AUTOSAR XML (schema 4-1-3)
standard types defined: boolean, sint8, uint16, uint32, uint8, boolean_CompuMethod, boolean_DataConstr, sint8_DataConstr, uint16_DataConstr, uint32_DataConstr, uint8_DataConstr, sint16
package /MICROSAR/Dem_swc/DataTypes
  5 x impl type:
    Dem_DebounceResetStatusType: compu {0=DEM_DEBOUNCE_STATUS_FREEZE, 1=DEM_DEBOUNCE_STATUS_RESET}, range raw 0..255, implementation-data-type=ImplementationDataTypes/uint8
    Dem_DTCFormatType: compu {0=DEM_DTC_FORMAT_OBD, 1=DEM_DTC_FORMAT_UDS, 2=DEM_DTC_FORMAT_J1939}, range raw 0..2, implementation-data-type=ImplementationDataTypes/uint8
    Dem_EventStatusType:
      compu {0=DEM_EVENT_STATUS_PASSED, 1=DEM_EVENT_STATUS_FAILED, 2=DEM_EVENT_STATUS_PREPASSED, 3=DEM_EVENT_STATUS_PREFAILED, 4=DEM_EVENT_STATUS_FDC_THRESHOLD_REACHED, 5=DEM_EVENT_STATUS_PASSED_CONDITIONS_NOT_FULFILLED, 6=DEM_EVENT_STATUS_FAILED_CONDITIONS_NOT_FULFILLED, 7=DEM_EVENT_STATUS_PREPASSED_CONDITIONS_NOT_FULFILLED, 8=DEM_EVENT_STATUS_PREFAILED_CONDITIONS_NOT_FULFILLED}
      range raw 0..255
      implementation-data-type=ImplementationDataTypes/uint8
    Dem_MaxDataValueType: category=ARRAY, sw-calibration-access=READ-ONLY
      element Dem_MaxDataValueTypeElement: array-size=14, array-size-semantics=FIXED-SIZE, implementation-data-type=ImplementationDataTypes/uint8
    Dem_UdsStatusByteType:
      compu {mask 1: 1=DEM_UDS_STATUS_TF (bit 0: TestFailed), mask 2: 2=DEM_UDS_STATUS_TFTOC (bit 1: TestFailedThisOperationCycle), mask 4: 4=DEM_UDS_STATUS_PDTC (bit 2: PendingDTC), mask 8: 8=DEM_UDS_STATUS_CDTC (bit 3: ConfirmedDTC), mask 16: 16=DEM_UDS_STATUS_TNCSLC (bit 4: TestNotCompletedSinceLastClear), mask 32: 32=DEM_UDS_STATUS_TFSLC (bit 5: TestFailedSinceLastClear), mask 64: 64=DEM_UDS_STATUS_TNCTOC (bit 6: TestNotCompletedThisOperationCycle), mask 128: 128=DEM_UDS_STATUS_WIR (bit 7: WarningIndicatorRequested)}
      range raw 0..255
      implementation-data-type=ImplementationDataTypes/uint8
package /MICROSAR/Dem_swc/Interfaces
  client server interface DiagnosticMonitor: is-service=true, service-kind=DIAGNOSTIC-EVENT-MANAGER
    11 x operation:
      GetDTCOfEvent: possible-error=[DEM_E_NO_DTC_AVAILABLE, E_NOT_OK]
        arg DTCFormat: type=Dem_DTCFormatType, direction=IN, server-argument-impl-policy=USE-ARGUMENT-TYPE
        arg DTCOfEvent: type=ImplementationDataTypes/uint32, direction=OUT, server-argument-impl-policy=USE-ARGUMENT-TYPE
      GetEventExtendedDataRecordEx: possible-error=[DEM_BUFFER_TOO_SMALL, DEM_NO_SUCH_ELEMENT, E_NOT_OK]
        arg RecordNumber: type=ImplementationDataTypes/uint8, direction=IN, server-argument-impl-policy=USE-ARGUMENT-TYPE
        arg DestBuffer: type=Dem_MaxDataValueType, direction=OUT, server-argument-impl-policy=USE-ARGUMENT-TYPE
        arg BufSize: type=ImplementationDataTypes/uint16, direction=INOUT, server-argument-impl-policy=USE-ARGUMENT-TYPE
      GetEventFailed: possible-error=E_NOT_OK
        arg EventFailed: type=ImplementationDataTypes/boolean, direction=OUT, server-argument-impl-policy=USE-ARGUMENT-TYPE
      GetEventFreezeFrameDataEx: possible-error=[DEM_BUFFER_TOO_SMALL, DEM_NO_SUCH_ELEMENT, E_NOT_OK]
        4 x arg, all with server-argument-impl-policy=USE-ARGUMENT-TYPE:
          RecordNumber: type=ImplementationDataTypes/uint8, direction=IN
          DataId: type=ImplementationDataTypes/uint16, direction=IN
          DestBuffer: type=Dem_MaxDataValueType, direction=OUT
          BufSize: type=ImplementationDataTypes/uint16, direction=INOUT
      GetEventStatus: possible-error=E_NOT_OK
        arg UDSStatusByte: type=Dem_UdsStatusByteType, direction=OUT, server-argument-impl-policy=USE-ARGUMENT-TYPE
      GetEventTested: possible-error=E_NOT_OK
        arg EventTested: type=ImplementationDataTypes/boolean, direction=OUT, server-argument-impl-policy=USE-ARGUMENT-TYPE
      GetEventUdsStatus: possible-error=E_NOT_OK
        arg UDSStatusByte: type=Dem_UdsStatusByteType, direction=OUT, server-argument-impl-policy=USE-ARGUMENT-TYPE
      GetFaultDetectionCounter: possible-error=[DEM_E_NO_FDC_AVAILABLE, E_NOT_OK]
        arg FaultDetectionCounter: type=sint8, direction=OUT, server-argument-impl-policy=USE-ARGUMENT-TYPE
      ResetEventDebounceStatus: possible-error=E_NOT_OK
        arg DebounceResetStatus: type=Dem_DebounceResetStatusType, direction=IN, server-argument-impl-policy=USE-ARGUMENT-TYPE
      ResetEventStatus: possible-error=E_NOT_OK
      SetEventStatus: possible-error=E_NOT_OK
        arg EventStatus: type=Dem_EventStatusType, direction=IN, server-argument-impl-policy=USE-ARGUMENT-TYPE
    5 x error:
      DEM_BUFFER_TOO_SMALL: error-code=21
      DEM_E_NO_DTC_AVAILABLE: error-code=10
      DEM_E_NO_FDC_AVAILABLE: error-code=14
      DEM_NO_SUCH_ELEMENT: error-code=48
      E_NOT_OK: error-code=1
package /UAES/ASW/ApplicationDataTypes
  7 x app type, all with category=VALUE, sw-calibration-access=READ-WRITE:
    I_q0p25_mA_s16: compu {phys=raw*0.25 for raw -INF..INF; unit mA}, range raw -32768..32767
    N_q1_rpm_u16: compu {phys=raw for raw -INF..INF; unit rpm}, range raw 0..65535
    P_q2_hPa_s16: compu {phys=raw*2; unit hPa}, range raw -32768..32767
    Perc_q0p0122_Perc_s16: compu {phys=raw*0.01220703125 for raw -INF..INF; unit %}, range raw -32768..32767
    T_q0p1_o273p14_DegC_s16: compu {phys=raw*0.1-273.14 for raw -INF..INF; unit DegC}, range raw -32768..32767
    Ti_q1_us_u32: compu {phys=raw for raw -INF..INF; unit us}, range phys 0..4294967295, raw 0..4294967295
    U_q1_mV_u16: compu {phys=raw for raw -INF..INF; unit mV}, range raw 0..65535
package /UAES/ASW/CompuMethods
  compu method CM_boolean: 0=FALSE, 1=TRUE
package /UAES/ASW/DataConstrs
  range DC_boolean: raw 0..1
  range DC_sint16: raw -32768..32767
  range DC_uint16: raw 0..65535
  range DC_uint32: raw 0..4294967295
  range DC_uint8: raw 0..255
package /UAES/ASW/DataTypeMappingSets
  data type mapping set DTMS_ChrgMngt_ComCnvTx
    data-type-maps:
      application-data-type=I_q0p25_mA_s16, implementation-data-type=sint16
      application-data-type=N_q1_rpm_u16, implementation-data-type=ImplementationDataTypes/uint16
      application-data-type=P_q2_hPa_s16, implementation-data-type=sint16
      application-data-type=Perc_q0p0122_Perc_s16, implementation-data-type=sint16
      application-data-type=T_q0p1_o273p14_DegC_s16, implementation-data-type=sint16
      application-data-type=Ti_q1_us_u32, implementation-data-type=ImplementationDataTypes/uint32
      application-data-type=U_q1_mV_u16, implementation-data-type=ImplementationDataTypes/uint16
package /UAES/ASW/PortInterfaces
  73 x sender receiver interface:
    AcChrgrIntkT_flgSRCMaxErr: invalidation-policy{data-element=AcChrgrIntkT_flgSRCMaxErr/Val, handle-invalid=DONT-INVALIDATE}
      data Val: sw-calibration-access=READ-ONLY, type=ImplementationDataTypes/boolean
    AcChrgrIntkT_flgSRCMinErr: invalidation-policy{data-element=AcChrgrIntkT_flgSRCMinErr/Val, handle-invalid=DONT-INVALIDATE}
      data Val: sw-calibration-access=READ-ONLY, type=ImplementationDataTypes/boolean
    AcChrgrIntkT_t: invalidation-policy{data-element=AcChrgrIntkT_t/Val, handle-invalid=DONT-INVALIDATE}
      data Val: sw-calibration-access=READ-ONLY, type=T_q0p1_o273p14_DegC_s16
    AcChrgrIntkT2_flgSRCMaxErr: invalidation-policy{data-element=AcChrgrIntkT2_flgSRCMaxErr/Val, handle-invalid=DONT-INVALIDATE}
      data Val: sw-calibration-access=READ-ONLY, type=ImplementationDataTypes/boolean
    AcChrgrIntkT2_flgSRCMinErr: invalidation-policy{data-element=AcChrgrIntkT2_flgSRCMinErr/Val, handle-invalid=DONT-INVALIDATE}
      data Val: sw-calibration-access=READ-ONLY, type=ImplementationDataTypes/boolean
    AcChrgrIntkT2_t: invalidation-policy{data-element=AcChrgrIntkT2_t/Val, handle-invalid=DONT-INVALIDATE}
      data Val: sw-calibration-access=READ-ONLY, type=T_q0p1_o273p14_DegC_s16
    BattU_bVoltEnbPinDiag: invalidation-policy{data-element=BattU_bVoltEnbPinDiag/Val, handle-invalid=DONT-INVALIDATE}
      data Val: sw-calibration-access=READ-ONLY, type=ImplementationDataTypes/boolean
    ChgrPlug_stPlgLock: invalidation-policy{data-element=ChgrPlug_stPlgLock/Val, handle-invalid=DONT-INVALIDATE}
      data Val: sw-calibration-access=READ-ONLY, type=ImplementationDataTypes/uint8
    ChrgIndcr_bBlueFaultSt: invalidation-policy{data-element=ChrgIndcr_bBlueFaultSt/Val, handle-invalid=DONT-INVALIDATE}
      data Val: sw-calibration-access=READ-ONLY, type=ImplementationDataTypes/boolean
    ChrgIndcr_bGreenFaultSt: invalidation-policy{data-element=ChrgIndcr_bGreenFaultSt/Val, handle-invalid=DONT-INVALIDATE}
      data Val: sw-calibration-access=READ-ONLY, type=ImplementationDataTypes/boolean
    ChrgIndcr_bRedFaultSt: invalidation-policy{data-element=ChrgIndcr_bRedFaultSt/Val, handle-invalid=DONT-INVALIDATE}
      data Val: sw-calibration-access=READ-ONLY, type=ImplementationDataTypes/boolean
    ChrgIndcr_rIndcr1: invalidation-policy{data-element=ChrgIndcr_rIndcr1/Val, handle-invalid=DONT-INVALIDATE}
      data Val: sw-calibration-access=READ-ONLY, type=Perc_q0p0122_Perc_s16
    ChrgIndcr_rIndcr2: invalidation-policy{data-element=ChrgIndcr_rIndcr2/Val, handle-invalid=DONT-INVALIDATE}
      data Val: sw-calibration-access=READ-ONLY, type=Perc_q0p0122_Perc_s16
    ChrgIndcr_rIndcr3: invalidation-policy{data-element=ChrgIndcr_rIndcr3/Val, handle-invalid=DONT-INVALIDATE}
      data Val: sw-calibration-access=READ-ONLY, type=Perc_q0p0122_Perc_s16
    ChrgPlgPosn_st: invalidation-policy{data-element=ChrgPlgPosn_st/Val, handle-invalid=DONT-INVALIDATE}
      data Val: sw-calibration-access=READ-ONLY, type=ImplementationDataTypes/uint8
    ChrgPlgPosn_stRaw: invalidation-policy{data-element=ChrgPlgPosn_stRaw/Val, handle-invalid=DONT-INVALIDATE}
      data Val: sw-calibration-access=READ-ONLY, type=ImplementationDataTypes/uint8
    ChrgPlgPosn_stRaw2: invalidation-policy{data-element=ChrgPlgPosn_stRaw2/Val, handle-invalid=DONT-INVALIDATE}
      data Val: sw-calibration-access=READ-ONLY, type=ImplementationDataTypes/uint8
    ComRx_u8UMM_UsageModeSt: invalidation-policy{data-element=ComRx_u8UMM_UsageModeSt/Val, handle-invalid=DONT-INVALIDATE}
      data Val: sw-calibration-access=READ-ONLY, type=ImplementationDataTypes/uint8
    ComTx_bACChgL1TempVoltOvr: invalidation-policy{data-element=ComTx_bACChgL1TempVoltOvr/Val, handle-invalid=DONT-INVALIDATE}
      data Val: sw-calibration-access=READ-ONLY, type=ImplementationDataTypes/boolean
    ComTx_bACChgL1TempVoltUnd: invalidation-policy{data-element=ComTx_bACChgL1TempVoltUnd/Val, handle-invalid=DONT-INVALIDATE}
      data Val: sw-calibration-access=READ-ONLY, type=ImplementationDataTypes/boolean
    ComTx_bACChgNTempVoltOvr: invalidation-policy{data-element=ComTx_bACChgNTempVoltOvr/Val, handle-invalid=DONT-INVALIDATE}
      data Val: sw-calibration-access=READ-ONLY, type=ImplementationDataTypes/boolean
    ComTx_bACChgNTempVoltUnd: invalidation-policy{data-element=ComTx_bACChgNTempVoltUnd/Val, handle-invalid=DONT-INVALIDATE}
      data Val: sw-calibration-access=READ-ONLY, type=ImplementationDataTypes/boolean
    ComTx_bACEleclocksSt1: invalidation-policy{data-element=ComTx_bACEleclocksSt1/Val, handle-invalid=DONT-INVALIDATE}
      data Val: sw-calibration-access=READ-ONLY, type=ImplementationDataTypes/boolean
    ComTx_bACEleclocksSt2: invalidation-policy{data-element=ComTx_bACEleclocksSt2/Val, handle-invalid=DONT-INVALIDATE}
      data Val: sw-calibration-access=READ-ONLY, type=ImplementationDataTypes/boolean
    ComTx_bDCChgDC1TempVoltOvr: invalidation-policy{data-element=ComTx_bDCChgDC1TempVoltOvr/Val, handle-invalid=DONT-INVALIDATE}
      data Val: sw-calibration-access=READ-ONLY, type=ImplementationDataTypes/boolean
    ComTx_bDCChgDC1TempVoltUnd: invalidation-policy{data-element=ComTx_bDCChgDC1TempVoltUnd/Val, handle-invalid=DONT-INVALIDATE}
      data Val: sw-calibration-access=READ-ONLY, type=ImplementationDataTypes/boolean
    ComTx_bDCChgDC2TempVoltOvr: invalidation-policy{data-element=ComTx_bDCChgDC2TempVoltOvr/Val, handle-invalid=DONT-INVALIDATE}
      data Val: sw-calibration-access=READ-ONLY, type=ImplementationDataTypes/boolean
    ComTx_bDCChgDC2TempVoltUnd: invalidation-policy{data-element=ComTx_bDCChgDC2TempVoltUnd/Val, handle-invalid=DONT-INVALIDATE}
      data Val: sw-calibration-access=READ-ONLY, type=ImplementationDataTypes/boolean
    ComTx_bDCchgpileA1voltVD: invalidation-policy{data-element=ComTx_bDCchgpileA1voltVD/Val, handle-invalid=DONT-INVALIDATE}
      data Val: sw-calibration-access=READ-ONLY, type=ImplementationDataTypes/boolean
    ComTx_bDCchgpileCC1voltVD: invalidation-policy{data-element=ComTx_bDCchgpileCC1voltVD/Val, handle-invalid=DONT-INVALIDATE}
      data Val: sw-calibration-access=READ-ONLY, type=ImplementationDataTypes/boolean
    ComTx_bDCchgpileCC2voltVD: invalidation-policy{data-element=ComTx_bDCchgpileCC2voltVD/Val, handle-invalid=DONT-INVALIDATE}
      data Val: sw-calibration-access=READ-ONLY, type=ImplementationDataTypes/boolean
    ComTx_bEL_BlueChargeLightFaultSt: invalidation-policy{data-element=ComTx_bEL_BlueChargeLightFaultSt/Val, handle-invalid=DONT-INVALIDATE}
      data Val: sw-calibration-access=READ-ONLY, type=ImplementationDataTypes/boolean
    ComTx_bEL_GreenChargeLightFaultSt: invalidation-policy{data-element=ComTx_bEL_GreenChargeLightFaultSt/Val, handle-invalid=DONT-INVALIDATE}
      data Val: sw-calibration-access=READ-ONLY, type=ImplementationDataTypes/boolean
    ComTx_bEL_RedChargeLightFaultSt: invalidation-policy{data-element=ComTx_bEL_RedChargeLightFaultSt/Val, handle-invalid=DONT-INVALIDATE}
      data Val: sw-calibration-access=READ-ONLY, type=ImplementationDataTypes/boolean
    ComTx_u16ACChgL1Temp: invalidation-policy{data-element=ComTx_u16ACChgL1Temp/Val, handle-invalid=DONT-INVALIDATE}
      data Val: sw-calibration-access=READ-ONLY, type=ImplementationDataTypes/uint16
    ComTx_u16ACChgNTemp: invalidation-policy{data-element=ComTx_u16ACChgNTemp/Val, handle-invalid=DONT-INVALIDATE}
      data Val: sw-calibration-access=READ-ONLY, type=ImplementationDataTypes/uint16
    ComTx_u16DCChgDC1Temp: invalidation-policy{data-element=ComTx_u16DCChgDC1Temp/Val, handle-invalid=DONT-INVALIDATE}
      data Val: sw-calibration-access=READ-ONLY, type=ImplementationDataTypes/uint16
    ComTx_u16DCChgDC2emp: invalidation-policy{data-element=ComTx_u16DCChgDC2emp/Val, handle-invalid=DONT-INVALIDATE}
      data Val: sw-calibration-access=READ-ONLY, type=ImplementationDataTypes/uint16
    ComTx_u16DCChgDC2Temp: invalidation-policy{data-element=ComTx_u16DCChgDC2Temp/Val, handle-invalid=DONT-INVALIDATE}
      data Val: sw-calibration-access=READ-ONLY, type=ImplementationDataTypes/uint16
    ComTx_u16DCchgpileA1volt: invalidation-policy{data-element=ComTx_u16DCchgpileA1volt/Val, handle-invalid=DONT-INVALIDATE}
      data Val: sw-calibration-access=READ-ONLY, type=ImplementationDataTypes/uint16
    ComTx_u8ACChgL1TempVD: invalidation-policy{data-element=ComTx_u8ACChgL1TempVD/Val, handle-invalid=DONT-INVALIDATE}
      data Val: sw-calibration-access=READ-ONLY, type=ImplementationDataTypes/uint8
    ComTx_u8ACChgNTempVD: invalidation-policy{data-element=ComTx_u8ACChgNTempVD/Val, handle-invalid=DONT-INVALIDATE}
      data Val: sw-calibration-access=READ-ONLY, type=ImplementationDataTypes/uint8
    ComTx_u8ACEleclocksSt: invalidation-policy{data-element=ComTx_u8ACEleclocksSt/Val, handle-invalid=DONT-INVALIDATE}
      data Val: sw-calibration-access=READ-ONLY, type=ImplementationDataTypes/uint8
    ComTx_u8DCChgDC1TempVD: invalidation-policy{data-element=ComTx_u8DCChgDC1TempVD/Val, handle-invalid=DONT-INVALIDATE}
      data Val: sw-calibration-access=READ-ONLY, type=ImplementationDataTypes/uint8
    ComTx_u8DCChgDC2TempVD: invalidation-policy{data-element=ComTx_u8DCChgDC2TempVD/Val, handle-invalid=DONT-INVALIDATE}
      data Val: sw-calibration-access=READ-ONLY, type=ImplementationDataTypes/uint8
    ComTx_u8DCchgpileCC1volt: invalidation-policy{data-element=ComTx_u8DCchgpileCC1volt/Val, handle-invalid=DONT-INVALIDATE}
      data Val: sw-calibration-access=READ-ONLY, type=ImplementationDataTypes/uint8
    ComTx_u8DCchgpileCC2volt: invalidation-policy{data-element=ComTx_u8DCchgpileCC2volt/Val, handle-invalid=DONT-INVALIDATE}
      data Val: sw-calibration-access=READ-ONLY, type=ImplementationDataTypes/uint8
    ComTx_u8EL_IndChargeLightSt: invalidation-policy{data-element=ComTx_u8EL_IndChargeLightSt/Val, handle-invalid=DONT-INVALIDATE}
      data Val: sw-calibration-access=READ-ONLY, type=ImplementationDataTypes/uint8
    ComTx_u8Elecunlockdrvst: invalidation-policy{data-element=ComTx_u8Elecunlockdrvst/Val, handle-invalid=DONT-INVALIDATE}
      data Val: sw-calibration-access=READ-ONLY, type=ImplementationDataTypes/uint8
    ComTx_u8ElecunlockM1diagnosisoupt: invalidation-policy{data-element=ComTx_u8ElecunlockM1diagnosisoupt/Val, handle-invalid=DONT-INVALIDATE}
      data Val: sw-calibration-access=READ-ONLY, type=ImplementationDataTypes/uint8
    ComTx_u8ElecunlockM1diagnosisoupt1: invalidation-policy{data-element=ComTx_u8ElecunlockM1diagnosisoupt1/Val, handle-invalid=DONT-INVALIDATE}
      data Val: sw-calibration-access=READ-ONLY, type=ImplementationDataTypes/uint8
    ComTx_u8ElecunlockM1diagnosisoupt2: invalidation-policy{data-element=ComTx_u8ElecunlockM1diagnosisoupt2/Val, handle-invalid=DONT-INVALIDATE}
      data Val: sw-calibration-access=READ-ONLY, type=ImplementationDataTypes/uint8
    ComTx_u8ElecunlockM2diagnosisoupt: invalidation-policy{data-element=ComTx_u8ElecunlockM2diagnosisoupt/Val, handle-invalid=DONT-INVALIDATE}
      data Val: sw-calibration-access=READ-ONLY, type=ImplementationDataTypes/uint8
    ComTx_u8ElecunlockM2diagnosisoupt1: invalidation-policy{data-element=ComTx_u8ElecunlockM2diagnosisoupt1/Val, handle-invalid=DONT-INVALIDATE}
      data Val: sw-calibration-access=READ-ONLY, type=ImplementationDataTypes/uint8
    ComTx_u8ElecunlockM2diagnosisoupt2: invalidation-policy{data-element=ComTx_u8ElecunlockM2diagnosisoupt2/Val, handle-invalid=DONT-INVALIDATE}
      data Val: sw-calibration-access=READ-ONLY, type=ImplementationDataTypes/uint8
    ComTx_u8ElecunlockProSt: invalidation-policy{data-element=ComTx_u8ElecunlockProSt/Val, handle-invalid=DONT-INVALIDATE}
      data Val: sw-calibration-access=READ-ONLY, type=ImplementationDataTypes/uint8
    DcChrgrIntkT_flgSRCMaxErr: invalidation-policy{data-element=DcChrgrIntkT_flgSRCMaxErr/Val, handle-invalid=DONT-INVALIDATE}
      data Val: sw-calibration-access=READ-ONLY, type=ImplementationDataTypes/boolean
    DcChrgrIntkT_flgSRCMinErr: invalidation-policy{data-element=DcChrgrIntkT_flgSRCMinErr/Val, handle-invalid=DONT-INVALIDATE}
      data Val: sw-calibration-access=READ-ONLY, type=ImplementationDataTypes/boolean
    DcChrgrIntkT_t: invalidation-policy{data-element=DcChrgrIntkT_t/Val, handle-invalid=DONT-INVALIDATE}
      data Val: sw-calibration-access=READ-ONLY, type=T_q0p1_o273p14_DegC_s16
    DcChrgrIntkT2_flgSRCMaxErr: invalidation-policy{data-element=DcChrgrIntkT2_flgSRCMaxErr/Val, handle-invalid=DONT-INVALIDATE}
      data Val: sw-calibration-access=READ-ONLY, type=ImplementationDataTypes/boolean
    DcChrgrIntkT2_flgSRCMinErr: invalidation-policy{data-element=DcChrgrIntkT2_flgSRCMinErr/Val, handle-invalid=DONT-INVALIDATE}
      data Val: sw-calibration-access=READ-ONLY, type=ImplementationDataTypes/boolean
    DcChrgrIntkT2_t: invalidation-policy{data-element=DcChrgrIntkT2_t/Val, handle-invalid=DONT-INVALIDATE}
      data Val: sw-calibration-access=READ-ONLY, type=T_q0p1_o273p14_DegC_s16
    DcChrgrPileU1_flgSRCMaxErr: invalidation-policy{data-element=DcChrgrPileU1_flgSRCMaxErr/Val, handle-invalid=DONT-INVALIDATE}
      data Val: sw-calibration-access=READ-ONLY, type=ImplementationDataTypes/boolean
    DcChrgrPileU1_flgSRCMinErr: invalidation-policy{data-element=DcChrgrPileU1_flgSRCMinErr/Val, handle-invalid=DONT-INVALIDATE}
      data Val: sw-calibration-access=READ-ONLY, type=ImplementationDataTypes/boolean
    DcChrgrPileU1_uRaw: invalidation-policy{data-element=DcChrgrPileU1_uRaw/Val, handle-invalid=DONT-INVALIDATE}
      data Val: sw-calibration-access=READ-ONLY, type=U_q1_mV_u16
    DcChrgrPileU2_flgSRCMaxErr: invalidation-policy{data-element=DcChrgrPileU2_flgSRCMaxErr/Val, handle-invalid=DONT-INVALIDATE}
      data Val: sw-calibration-access=READ-ONLY, type=ImplementationDataTypes/boolean
    DcChrgrPileU2_flgSRCMinErr: invalidation-policy{data-element=DcChrgrPileU2_flgSRCMinErr/Val, handle-invalid=DONT-INVALIDATE}
      data Val: sw-calibration-access=READ-ONLY, type=ImplementationDataTypes/boolean
    DcChrgrPileU2_uRaw: invalidation-policy{data-element=DcChrgrPileU2_uRaw/Val, handle-invalid=DONT-INVALIDATE}
      data Val: sw-calibration-access=READ-ONLY, type=U_q1_mV_u16
    DcChrgrPileU3_flgSRCMaxErr: invalidation-policy{data-element=DcChrgrPileU3_flgSRCMaxErr/Val, handle-invalid=DONT-INVALIDATE}
      data Val: sw-calibration-access=READ-ONLY, type=ImplementationDataTypes/boolean
    DcChrgrPileU3_flgSRCMinErr: invalidation-policy{data-element=DcChrgrPileU3_flgSRCMinErr/Val, handle-invalid=DONT-INVALIDATE}
      data Val: sw-calibration-access=READ-ONLY, type=ImplementationDataTypes/boolean
    DcChrgrPileU3_uRaw: invalidation-policy{data-element=DcChrgrPileU3_uRaw/Val, handle-invalid=DONT-INVALIDATE}
      data Val: sw-calibration-access=READ-ONLY, type=U_q1_mV_u16
    IntlckChrgPlg_rActr: invalidation-policy{data-element=IntlckChrgPlg_rActr/Val, handle-invalid=DONT-INVALIDATE}
      data Val: sw-calibration-access=READ-ONLY, type=Perc_q0p0122_Perc_s16
    VehCoorn_stPwrMod: invalidation-policy{data-element=VehCoorn_stPwrMod/Val, handle-invalid=DONT-INVALIDATE}
      data Val: sw-calibration-access=READ-ONLY, type=ImplementationDataTypes/uint8
package /UAES/ASW/Units
  8 x unit, all with factor-si-to-unit=1, offset-si-to-unit=0:
    DegC: display-name=DegC
    hPa: display-name=hPa
    mA: display-name=mA
    mV: display-name=mV
    NoUnit
    Perc: display-name=%
    rpm
    us: display-name=us
package /UAES/DataConstrs
  range DC_UInt16: raw 0..65535
package /UAES/SwComponentTypes
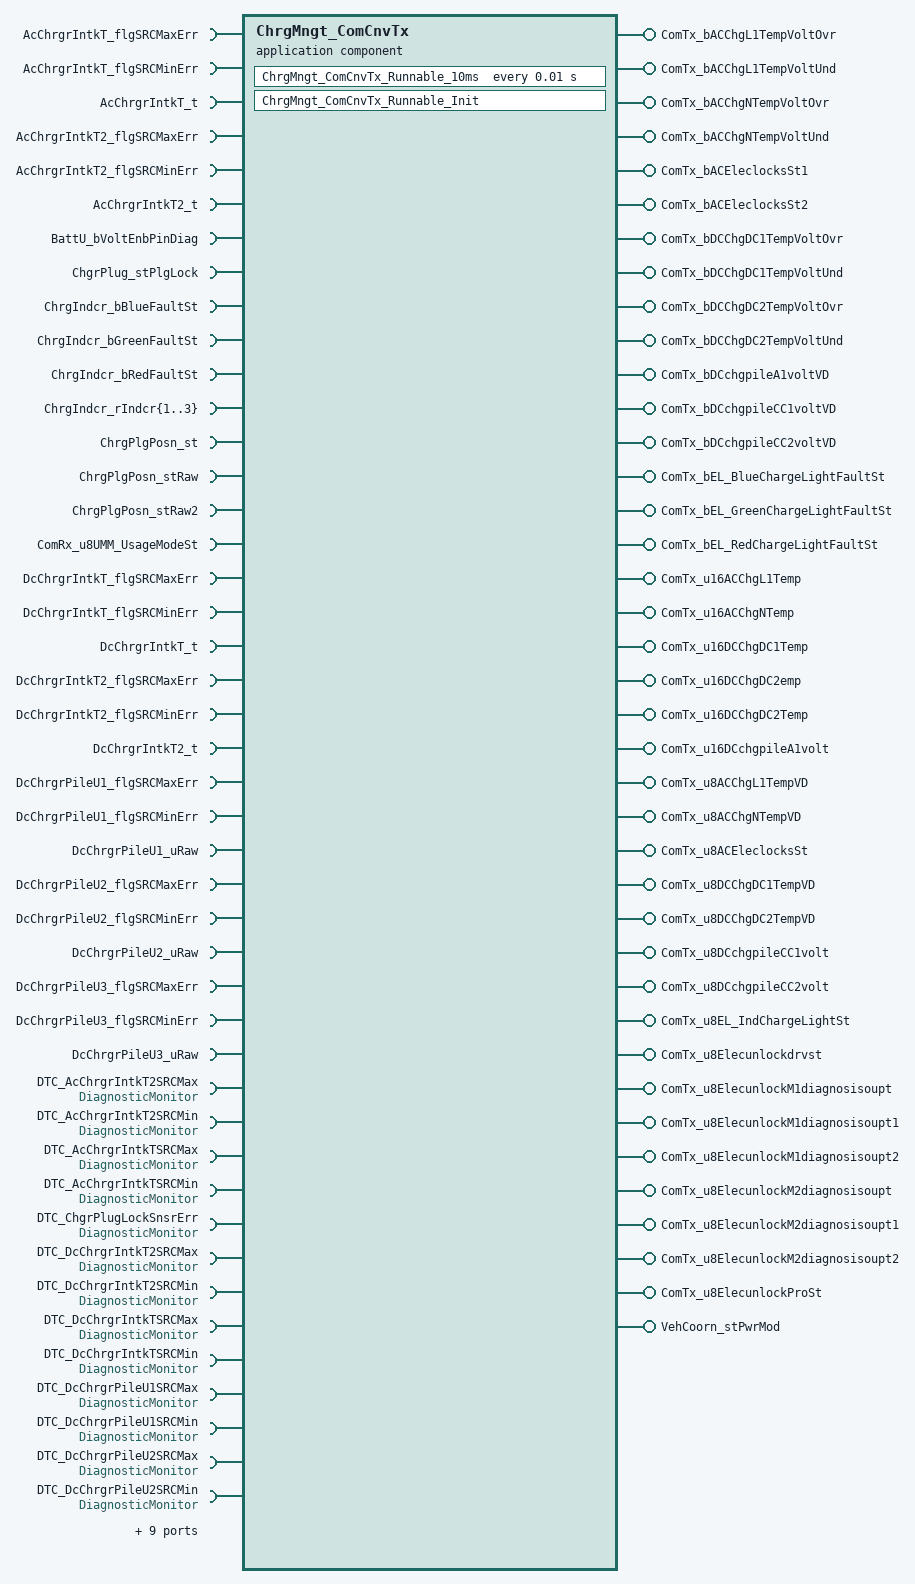
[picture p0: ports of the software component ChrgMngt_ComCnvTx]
  application sw component type ChrgMngt_ComCnvTx
    39 x provide port:
      ComTx_bACChgL1TempVoltOvr: nonqueued-sender-com-spec{data-element=ComTx_bACChgL1TempVoltOvr/Val, init-value=0}, provided-interface=ComTx_bACChgL1TempVoltOvr
      ComTx_bACChgL1TempVoltUnd: nonqueued-sender-com-spec{data-element=ComTx_bACChgL1TempVoltUnd/Val, init-value=0}, provided-interface=ComTx_bACChgL1TempVoltUnd
      ComTx_bACChgNTempVoltOvr: nonqueued-sender-com-spec{data-element=ComTx_bACChgNTempVoltOvr/Val, init-value=0}, provided-interface=ComTx_bACChgNTempVoltOvr
      ComTx_bACChgNTempVoltUnd: nonqueued-sender-com-spec{data-element=ComTx_bACChgNTempVoltUnd/Val, init-value=0}, provided-interface=ComTx_bACChgNTempVoltUnd
      ComTx_bACEleclocksSt1: nonqueued-sender-com-spec{data-element=ComTx_bACEleclocksSt1/Val, init-value=0}, provided-interface=ComTx_bACEleclocksSt1
      ComTx_bACEleclocksSt2: nonqueued-sender-com-spec{data-element=ComTx_bACEleclocksSt2/Val, init-value=0}, provided-interface=ComTx_bACEleclocksSt2
      ComTx_bDCChgDC1TempVoltOvr: nonqueued-sender-com-spec{data-element=ComTx_bDCChgDC1TempVoltOvr/Val, init-value=0}, provided-interface=ComTx_bDCChgDC1TempVoltOvr
      ComTx_bDCChgDC1TempVoltUnd: nonqueued-sender-com-spec{data-element=ComTx_bDCChgDC1TempVoltUnd/Val, init-value=0}, provided-interface=ComTx_bDCChgDC1TempVoltUnd
      ComTx_bDCChgDC2TempVoltOvr: nonqueued-sender-com-spec{data-element=ComTx_bDCChgDC2TempVoltOvr/Val, init-value=0}, provided-interface=ComTx_bDCChgDC2TempVoltOvr
      ComTx_bDCChgDC2TempVoltUnd: nonqueued-sender-com-spec{data-element=ComTx_bDCChgDC2TempVoltUnd/Val, init-value=0}, provided-interface=ComTx_bDCChgDC2TempVoltUnd
      ComTx_bDCchgpileA1voltVD: nonqueued-sender-com-spec{data-element=ComTx_bDCchgpileA1voltVD/Val, init-value=0}, provided-interface=ComTx_bDCchgpileA1voltVD
      ComTx_bDCchgpileCC1voltVD: nonqueued-sender-com-spec{data-element=ComTx_bDCchgpileCC1voltVD/Val, init-value=0}, provided-interface=ComTx_bDCchgpileCC1voltVD
      ComTx_bDCchgpileCC2voltVD: nonqueued-sender-com-spec{data-element=ComTx_bDCchgpileCC2voltVD/Val, init-value=0}, provided-interface=ComTx_bDCchgpileCC2voltVD
      ComTx_bEL_BlueChargeLightFaultSt: nonqueued-sender-com-spec{data-element=ComTx_bEL_BlueChargeLightFaultSt/Val, init-value=0}, provided-interface=ComTx_bEL_BlueChargeLightFaultSt
      ComTx_bEL_GreenChargeLightFaultSt: nonqueued-sender-com-spec{data-element=ComTx_bEL_GreenChargeLightFaultSt/Val, init-value=0}, provided-interface=ComTx_bEL_GreenChargeLightFaultSt
      ComTx_bEL_RedChargeLightFaultSt: nonqueued-sender-com-spec{data-element=ComTx_bEL_RedChargeLightFaultSt/Val, init-value=0}, provided-interface=ComTx_bEL_RedChargeLightFaultSt
      ComTx_u16ACChgL1Temp: nonqueued-sender-com-spec{data-element=ComTx_u16ACChgL1Temp/Val, init-value=0}, provided-interface=ComTx_u16ACChgL1Temp
      ComTx_u16ACChgNTemp: nonqueued-sender-com-spec{data-element=ComTx_u16ACChgNTemp/Val, init-value=0}, provided-interface=ComTx_u16ACChgNTemp
      ComTx_u16DCChgDC1Temp: nonqueued-sender-com-spec{data-element=ComTx_u16DCChgDC1Temp/Val, init-value=0}, provided-interface=ComTx_u16DCChgDC1Temp
      ComTx_u16DCChgDC2emp: nonqueued-sender-com-spec{data-element=ComTx_u16DCChgDC2emp/Val, init-value=0}, provided-interface=ComTx_u16DCChgDC2emp
      ComTx_u16DCChgDC2Temp: nonqueued-sender-com-spec{data-element=ComTx_u16DCChgDC2Temp/Val, init-value=0}, provided-interface=ComTx_u16DCChgDC2Temp
      ComTx_u16DCchgpileA1volt: nonqueued-sender-com-spec{data-element=ComTx_u16DCchgpileA1volt/Val, init-value=0}, provided-interface=ComTx_u16DCchgpileA1volt
      ComTx_u8ACChgL1TempVD: nonqueued-sender-com-spec{data-element=ComTx_u8ACChgL1TempVD/Val, init-value=0}, provided-interface=ComTx_u8ACChgL1TempVD
      ComTx_u8ACChgNTempVD: nonqueued-sender-com-spec{data-element=ComTx_u8ACChgNTempVD/Val, init-value=0}, provided-interface=ComTx_u8ACChgNTempVD
      ComTx_u8ACEleclocksSt: nonqueued-sender-com-spec{data-element=ComTx_u8ACEleclocksSt/Val, init-value=0}, provided-interface=ComTx_u8ACEleclocksSt
      ComTx_u8DCChgDC1TempVD: nonqueued-sender-com-spec{data-element=ComTx_u8DCChgDC1TempVD/Val, init-value=0}, provided-interface=ComTx_u8DCChgDC1TempVD
      ComTx_u8DCChgDC2TempVD: nonqueued-sender-com-spec{data-element=ComTx_u8DCChgDC2TempVD/Val, init-value=0}, provided-interface=ComTx_u8DCChgDC2TempVD
      ComTx_u8DCchgpileCC1volt: nonqueued-sender-com-spec{data-element=ComTx_u8DCchgpileCC1volt/Val, init-value=0}, provided-interface=ComTx_u8DCchgpileCC1volt
      ComTx_u8DCchgpileCC2volt: nonqueued-sender-com-spec{data-element=ComTx_u8DCchgpileCC2volt/Val, init-value=0}, provided-interface=ComTx_u8DCchgpileCC2volt
      ComTx_u8EL_IndChargeLightSt: nonqueued-sender-com-spec{data-element=ComTx_u8EL_IndChargeLightSt/Val, init-value=0}, provided-interface=ComTx_u8EL_IndChargeLightSt
      ComTx_u8Elecunlockdrvst: nonqueued-sender-com-spec{data-element=ComTx_u8Elecunlockdrvst/Val, init-value=0}, provided-interface=ComTx_u8Elecunlockdrvst
      ComTx_u8ElecunlockM1diagnosisoupt: nonqueued-sender-com-spec{data-element=ComTx_u8ElecunlockM1diagnosisoupt/Val, init-value=0}, provided-interface=ComTx_u8ElecunlockM1diagnosisoupt
      ComTx_u8ElecunlockM1diagnosisoupt1: nonqueued-sender-com-spec{data-element=ComTx_u8ElecunlockM1diagnosisoupt1/Val, init-value=0}, provided-interface=ComTx_u8ElecunlockM1diagnosisoupt1
      ComTx_u8ElecunlockM1diagnosisoupt2: nonqueued-sender-com-spec{data-element=ComTx_u8ElecunlockM1diagnosisoupt2/Val, init-value=0}, provided-interface=ComTx_u8ElecunlockM1diagnosisoupt2
      ComTx_u8ElecunlockM2diagnosisoupt: nonqueued-sender-com-spec{data-element=ComTx_u8ElecunlockM2diagnosisoupt/Val, init-value=0}, provided-interface=ComTx_u8ElecunlockM2diagnosisoupt
      ComTx_u8ElecunlockM2diagnosisoupt1: nonqueued-sender-com-spec{data-element=ComTx_u8ElecunlockM2diagnosisoupt1/Val, init-value=0}, provided-interface=ComTx_u8ElecunlockM2diagnosisoupt1
      ComTx_u8ElecunlockM2diagnosisoupt2: nonqueued-sender-com-spec{data-element=ComTx_u8ElecunlockM2diagnosisoupt2/Val, init-value=0}, provided-interface=ComTx_u8ElecunlockM2diagnosisoupt2
      ComTx_u8ElecunlockProSt: nonqueued-sender-com-spec{data-element=ComTx_u8ElecunlockProSt/Val, init-value=0}, provided-interface=ComTx_u8ElecunlockProSt
      VehCoorn_stPwrMod: nonqueued-sender-com-spec{data-element=VehCoorn_stPwrMod/Val, init-value=0}, provided-interface=VehCoorn_stPwrMod
    55 x require port:
      AcChrgrIntkT_flgSRCMaxErr: nonqueued-receiver-com-spec{data-element=AcChrgrIntkT_flgSRCMaxErr/Val, filter=data-filter-type=ALWAYS, init-value=0}, required-interface=AcChrgrIntkT_flgSRCMaxErr
      AcChrgrIntkT_flgSRCMinErr: nonqueued-receiver-com-spec{data-element=AcChrgrIntkT_flgSRCMinErr/Val, filter=data-filter-type=ALWAYS, init-value=0}, required-interface=AcChrgrIntkT_flgSRCMinErr
      AcChrgrIntkT_t: nonqueued-receiver-com-spec{data-element=AcChrgrIntkT_t/Val, filter=data-filter-type=ALWAYS, init-value=0}, required-interface=AcChrgrIntkT_t
      AcChrgrIntkT2_flgSRCMaxErr: nonqueued-receiver-com-spec{data-element=AcChrgrIntkT2_flgSRCMaxErr/Val, filter=data-filter-type=ALWAYS, init-value=0}, required-interface=AcChrgrIntkT2_flgSRCMaxErr
      AcChrgrIntkT2_flgSRCMinErr: nonqueued-receiver-com-spec{data-element=AcChrgrIntkT2_flgSRCMinErr/Val, filter=data-filter-type=ALWAYS, init-value=0}, required-interface=AcChrgrIntkT2_flgSRCMinErr
      AcChrgrIntkT2_t: nonqueued-receiver-com-spec{data-element=AcChrgrIntkT2_t/Val, filter=data-filter-type=ALWAYS, init-value=0}, required-interface=AcChrgrIntkT2_t
      BattU_bVoltEnbPinDiag: nonqueued-receiver-com-spec{data-element=BattU_bVoltEnbPinDiag/Val, filter=data-filter-type=ALWAYS, init-value=0}, required-interface=BattU_bVoltEnbPinDiag
      ChgrPlug_stPlgLock: nonqueued-receiver-com-spec{data-element=ChgrPlug_stPlgLock/Val, filter=data-filter-type=ALWAYS, init-value=0}, required-interface=ChgrPlug_stPlgLock
      ChrgIndcr_bBlueFaultSt: nonqueued-receiver-com-spec{data-element=ChrgIndcr_bBlueFaultSt/Val, filter=data-filter-type=ALWAYS, init-value=0}, required-interface=ChrgIndcr_bBlueFaultSt
      ChrgIndcr_bGreenFaultSt: nonqueued-receiver-com-spec{data-element=ChrgIndcr_bGreenFaultSt/Val, filter=data-filter-type=ALWAYS, init-value=0}, required-interface=ChrgIndcr_bGreenFaultSt
      ChrgIndcr_bRedFaultSt: nonqueued-receiver-com-spec{data-element=ChrgIndcr_bRedFaultSt/Val, filter=data-filter-type=ALWAYS, init-value=0}, required-interface=ChrgIndcr_bRedFaultSt
      ChrgIndcr_rIndcr{1..3}: nonqueued-receiver-com-spec{data-element=ChrgIndcr_rIndcr{1..3}/Val, filter=data-filter-type=ALWAYS, init-value=0}, required-interface=ChrgIndcr_rIndcr{1..3}
      ChrgPlgPosn_st: nonqueued-receiver-com-spec{data-element=ChrgPlgPosn_st/Val, filter=data-filter-type=ALWAYS, init-value=0}, required-interface=ChrgPlgPosn_st
      ChrgPlgPosn_stRaw: nonqueued-receiver-com-spec{data-element=ChrgPlgPosn_stRaw/Val, filter=data-filter-type=ALWAYS, init-value=0}, required-interface=ChrgPlgPosn_stRaw
      ChrgPlgPosn_stRaw2: nonqueued-receiver-com-spec{data-element=ChrgPlgPosn_stRaw2/Val, filter=data-filter-type=ALWAYS, init-value=0}, required-interface=ChrgPlgPosn_stRaw2
      ComRx_u8UMM_UsageModeSt: nonqueued-receiver-com-spec{data-element=ComRx_u8UMM_UsageModeSt/Val, filter=data-filter-type=ALWAYS, init-value=0}, required-interface=ComRx_u8UMM_UsageModeSt
      DcChrgrIntkT_flgSRCMaxErr: nonqueued-receiver-com-spec{data-element=DcChrgrIntkT_flgSRCMaxErr/Val, filter=data-filter-type=ALWAYS, init-value=0}, required-interface=DcChrgrIntkT_flgSRCMaxErr
      DcChrgrIntkT_flgSRCMinErr: nonqueued-receiver-com-spec{data-element=DcChrgrIntkT_flgSRCMinErr/Val, filter=data-filter-type=ALWAYS, init-value=0}, required-interface=DcChrgrIntkT_flgSRCMinErr
      DcChrgrIntkT_t: nonqueued-receiver-com-spec{data-element=DcChrgrIntkT_t/Val, filter=data-filter-type=ALWAYS, init-value=0}, required-interface=DcChrgrIntkT_t
      DcChrgrIntkT2_flgSRCMaxErr: nonqueued-receiver-com-spec{data-element=DcChrgrIntkT2_flgSRCMaxErr/Val, filter=data-filter-type=ALWAYS, init-value=0}, required-interface=DcChrgrIntkT2_flgSRCMaxErr
      DcChrgrIntkT2_flgSRCMinErr: nonqueued-receiver-com-spec{data-element=DcChrgrIntkT2_flgSRCMinErr/Val, filter=data-filter-type=ALWAYS, init-value=0}, required-interface=DcChrgrIntkT2_flgSRCMinErr
      DcChrgrIntkT2_t: nonqueued-receiver-com-spec{data-element=DcChrgrIntkT2_t/Val, filter=data-filter-type=ALWAYS, init-value=0}, required-interface=DcChrgrIntkT2_t
      DcChrgrPileU1_flgSRCMaxErr: nonqueued-receiver-com-spec{data-element=DcChrgrPileU1_flgSRCMaxErr/Val, filter=data-filter-type=ALWAYS, init-value=0}, required-interface=DcChrgrPileU1_flgSRCMaxErr
      DcChrgrPileU1_flgSRCMinErr: nonqueued-receiver-com-spec{data-element=DcChrgrPileU1_flgSRCMinErr/Val, filter=data-filter-type=ALWAYS, init-value=0}, required-interface=DcChrgrPileU1_flgSRCMinErr
      DcChrgrPileU1_uRaw: nonqueued-receiver-com-spec{data-element=DcChrgrPileU1_uRaw/Val, filter=data-filter-type=ALWAYS, init-value=0}, required-interface=DcChrgrPileU1_uRaw
      DcChrgrPileU2_flgSRCMaxErr: nonqueued-receiver-com-spec{data-element=DcChrgrPileU2_flgSRCMaxErr/Val, filter=data-filter-type=ALWAYS, init-value=0}, required-interface=DcChrgrPileU2_flgSRCMaxErr
      DcChrgrPileU2_flgSRCMinErr: nonqueued-receiver-com-spec{data-element=DcChrgrPileU2_flgSRCMinErr/Val, filter=data-filter-type=ALWAYS, init-value=0}, required-interface=DcChrgrPileU2_flgSRCMinErr
      DcChrgrPileU2_uRaw: nonqueued-receiver-com-spec{data-element=DcChrgrPileU2_uRaw/Val, filter=data-filter-type=ALWAYS, init-value=0}, required-interface=DcChrgrPileU2_uRaw
      DcChrgrPileU3_flgSRCMaxErr: nonqueued-receiver-com-spec{data-element=DcChrgrPileU3_flgSRCMaxErr/Val, filter=data-filter-type=ALWAYS, init-value=0}, required-interface=DcChrgrPileU3_flgSRCMaxErr
      DcChrgrPileU3_flgSRCMinErr: nonqueued-receiver-com-spec{data-element=DcChrgrPileU3_flgSRCMinErr/Val, filter=data-filter-type=ALWAYS, init-value=0}, required-interface=DcChrgrPileU3_flgSRCMinErr
      DcChrgrPileU3_uRaw: nonqueued-receiver-com-spec{data-element=DcChrgrPileU3_uRaw/Val, filter=data-filter-type=ALWAYS, init-value=0}, required-interface=DcChrgrPileU3_uRaw
      DTC_AcChrgrIntkT2SRCMax: required-interface=DiagnosticMonitor
        required-com-specs:
          GetDTCOfEvent
          GetEventExtendedDataRecordEx
          GetEventFailed
          GetEventFreezeFrameDataEx
          GetEventStatus
          GetEventTested
          GetEventUdsStatus
          GetFaultDetectionCounter
          ResetEventDebounceStatus
          ResetEventStatus
          SetEventStatus
      DTC_AcChrgrIntkT2SRCMin: required-interface=DiagnosticMonitor
        required-com-specs:
          GetDTCOfEvent
          GetEventExtendedDataRecordEx
          GetEventFailed
          GetEventFreezeFrameDataEx
          GetEventStatus
          GetEventTested
          GetEventUdsStatus
          GetFaultDetectionCounter
          ResetEventDebounceStatus
          ResetEventStatus
          SetEventStatus
      DTC_AcChrgrIntkTSRCMax: required-interface=DiagnosticMonitor
        required-com-specs:
          GetDTCOfEvent
          GetEventExtendedDataRecordEx
          GetEventFailed
          GetEventFreezeFrameDataEx
          GetEventStatus
          GetEventTested
          GetEventUdsStatus
          GetFaultDetectionCounter
          ResetEventDebounceStatus
          ResetEventStatus
          SetEventStatus
      DTC_AcChrgrIntkTSRCMin: required-interface=DiagnosticMonitor
        required-com-specs:
          GetDTCOfEvent
          GetEventExtendedDataRecordEx
          GetEventFailed
          GetEventFreezeFrameDataEx
          GetEventStatus
          GetEventTested
          GetEventUdsStatus
          GetFaultDetectionCounter
          ResetEventDebounceStatus
          ResetEventStatus
          SetEventStatus
      DTC_ChgrPlugLockSnsrErr: required-interface=DiagnosticMonitor
        required-com-specs:
          GetDTCOfEvent
          GetEventExtendedDataRecordEx
          GetEventFailed
          GetEventFreezeFrameDataEx
          GetEventStatus
          GetEventTested
          GetEventUdsStatus
          GetFaultDetectionCounter
          ResetEventDebounceStatus
          ResetEventStatus
          SetEventStatus
      DTC_DcChrgrIntkT2SRCMax: required-interface=DiagnosticMonitor
        required-com-specs:
          GetDTCOfEvent
          GetEventExtendedDataRecordEx
          GetEventFailed
          GetEventFreezeFrameDataEx
          GetEventStatus
          GetEventTested
          GetEventUdsStatus
          GetFaultDetectionCounter
          ResetEventDebounceStatus
          ResetEventStatus
          SetEventStatus
      DTC_DcChrgrIntkT2SRCMin: required-interface=DiagnosticMonitor
        required-com-specs:
          GetDTCOfEvent
          GetEventExtendedDataRecordEx
          GetEventFailed
          GetEventFreezeFrameDataEx
          GetEventStatus
          GetEventTested
          GetEventUdsStatus
          GetFaultDetectionCounter
          ResetEventDebounceStatus
          ResetEventStatus
          SetEventStatus
      DTC_DcChrgrIntkTSRCMax: required-interface=DiagnosticMonitor
        required-com-specs:
          GetDTCOfEvent
          GetEventExtendedDataRecordEx
          GetEventFailed
          GetEventFreezeFrameDataEx
          GetEventStatus
          GetEventTested
          GetEventUdsStatus
          GetFaultDetectionCounter
          ResetEventDebounceStatus
          ResetEventStatus
          SetEventStatus
      DTC_DcChrgrIntkTSRCMin: required-interface=DiagnosticMonitor
        required-com-specs:
          GetDTCOfEvent
          GetEventExtendedDataRecordEx
          GetEventFailed
          GetEventFreezeFrameDataEx
          GetEventStatus
          GetEventTested
          GetEventUdsStatus
          GetFaultDetectionCounter
          ResetEventDebounceStatus
          ResetEventStatus
          SetEventStatus
      DTC_DcChrgrPileU1SRCMax: required-interface=DiagnosticMonitor
        required-com-specs:
          GetDTCOfEvent
          GetEventExtendedDataRecordEx
          GetEventFailed
          GetEventFreezeFrameDataEx
          GetEventStatus
          GetEventTested
          GetEventUdsStatus
          GetFaultDetectionCounter
          ResetEventDebounceStatus
          ResetEventStatus
          SetEventStatus
      DTC_DcChrgrPileU1SRCMin: required-interface=DiagnosticMonitor
        required-com-specs:
          GetDTCOfEvent
          GetEventExtendedDataRecordEx
          GetEventFailed
          GetEventFreezeFrameDataEx
          GetEventStatus
          GetEventTested
          GetEventUdsStatus
          GetFaultDetectionCounter
          ResetEventDebounceStatus
          ResetEventStatus
          SetEventStatus
      DTC_DcChrgrPileU2SRCMax: required-interface=DiagnosticMonitor
        required-com-specs:
          GetDTCOfEvent
          GetEventExtendedDataRecordEx
          GetEventFailed
          GetEventFreezeFrameDataEx
          GetEventStatus
          GetEventTested
          GetEventUdsStatus
          GetFaultDetectionCounter
          ResetEventDebounceStatus
          ResetEventStatus
          SetEventStatus
      DTC_DcChrgrPileU2SRCMin: required-interface=DiagnosticMonitor
        required-com-specs:
          GetDTCOfEvent
          GetEventExtendedDataRecordEx
          GetEventFailed
          GetEventFreezeFrameDataEx
          GetEventStatus
          GetEventTested
          GetEventUdsStatus
          GetFaultDetectionCounter
          ResetEventDebounceStatus
          ResetEventStatus
          SetEventStatus
      DTC_DcChrgrPileU3SRCMax: required-interface=DiagnosticMonitor
        required-com-specs:
          GetDTCOfEvent
          GetEventExtendedDataRecordEx
          GetEventFailed
          GetEventFreezeFrameDataEx
          GetEventStatus
          GetEventTested
          GetEventUdsStatus
          GetFaultDetectionCounter
          ResetEventDebounceStatus
          ResetEventStatus
          SetEventStatus
      DTC_DcChrgrPileU3SRCMin: required-interface=DiagnosticMonitor
        required-com-specs:
          GetDTCOfEvent
          GetEventExtendedDataRecordEx
          GetEventFailed
          GetEventFreezeFrameDataEx
          GetEventStatus
          GetEventTested
          GetEventUdsStatus
          GetFaultDetectionCounter
          ResetEventDebounceStatus
          ResetEventStatus
          SetEventStatus
      DTC_IntlckChrgPlgHBrgOL1: required-interface=DiagnosticMonitor
        required-com-specs:
          GetDTCOfEvent
          GetEventExtendedDataRecordEx
          GetEventFailed
          GetEventFreezeFrameDataEx
          GetEventStatus
          GetEventTested
          GetEventUdsStatus
          GetFaultDetectionCounter
          ResetEventDebounceStatus
          ResetEventStatus
          SetEventStatus
      DTC_IntlckChrgPlgHBrgOL2: required-interface=DiagnosticMonitor
        required-com-specs:
          GetDTCOfEvent
          GetEventExtendedDataRecordEx
          GetEventFailed
          GetEventFreezeFrameDataEx
          GetEventStatus
          GetEventTested
          GetEventUdsStatus
          GetFaultDetectionCounter
          ResetEventDebounceStatus
          ResetEventStatus
          SetEventStatus
      DTC_IntlckChrgPlgHBrgSCB1: required-interface=DiagnosticMonitor
        required-com-specs:
          GetDTCOfEvent
          GetEventExtendedDataRecordEx
          GetEventFailed
          GetEventFreezeFrameDataEx
          GetEventStatus
          GetEventTested
          GetEventUdsStatus
          GetFaultDetectionCounter
          ResetEventDebounceStatus
          ResetEventStatus
          SetEventStatus
      DTC_IntlckChrgPlgHBrgSCB2: required-interface=DiagnosticMonitor
        required-com-specs:
          GetDTCOfEvent
          GetEventExtendedDataRecordEx
          GetEventFailed
          GetEventFreezeFrameDataEx
          GetEventStatus
          GetEventTested
          GetEventUdsStatus
          GetFaultDetectionCounter
          ResetEventDebounceStatus
          ResetEventStatus
          SetEventStatus
      DTC_IntlckChrgPlgHBrgSCG1: required-interface=DiagnosticMonitor
        required-com-specs:
          GetDTCOfEvent
          GetEventExtendedDataRecordEx
          GetEventFailed
          GetEventFreezeFrameDataEx
          GetEventStatus
          GetEventTested
          GetEventUdsStatus
          GetFaultDetectionCounter
          ResetEventDebounceStatus
          ResetEventStatus
          SetEventStatus
      DTC_IntlckChrgPlgHBrgSCG2: required-interface=DiagnosticMonitor
        required-com-specs:
          GetDTCOfEvent
          GetEventExtendedDataRecordEx
          GetEventFailed
          GetEventFreezeFrameDataEx
          GetEventStatus
          GetEventTested
          GetEventUdsStatus
          GetFaultDetectionCounter
          ResetEventDebounceStatus
          ResetEventStatus
          SetEventStatus
      IntlckChrgPlg_rActr: nonqueued-receiver-com-spec{data-element=IntlckChrgPlg_rActr/Val, filter=data-filter-type=ALWAYS, init-value=0}, required-interface=IntlckChrgPlg_rActr
    behavior ChrgMngt_ComCnvTx_InternalBehavior: data-type-mapping=DTMS_ChrgMngt_ComCnvTx
      timing event TMT_ChrgMngt_ComCnvTx_Runnable_10ms: start-on-event=ChrgMngt_ComCnvTx_Runnable_10ms, period=0.01
      init event ChrgMngt_ComCnvTx_InitEvent: start-on-event=ChrgMngt_ComCnvTx_Runnable_Init
      runnable ChrgMngt_ComCnvTx_Runnable_10ms
        data-read-access:
          34 x access:
            READ_AcChrgrIntkT_flgSRCMaxErr_Val: accessed-variable=AcChrgrIntkT_flgSRCMaxErr.Val
            READ_AcChrgrIntkT_flgSRCMinErr_Val: accessed-variable=AcChrgrIntkT_flgSRCMinErr.Val
            READ_AcChrgrIntkT_t_Val: accessed-variable=AcChrgrIntkT_t.Val
            READ_AcChrgrIntkT2_flgSRCMaxErr_Val: accessed-variable=AcChrgrIntkT2_flgSRCMaxErr.Val
            READ_AcChrgrIntkT2_flgSRCMinErr_Val: accessed-variable=AcChrgrIntkT2_flgSRCMinErr.Val
            READ_AcChrgrIntkT2_t_Val: accessed-variable=AcChrgrIntkT2_t.Val
            READ_BattU_bVoltEnbPinDiag_Val: accessed-variable=BattU_bVoltEnbPinDiag.Val
            READ_ChgrPlug_stPlgLock_Val: accessed-variable=ChgrPlug_stPlgLock.Val
            READ_ChrgIndcr_bBlueFaultSt_Val: accessed-variable=ChrgIndcr_bBlueFaultSt.Val
            READ_ChrgIndcr_bGreenFaultSt_Val: accessed-variable=ChrgIndcr_bGreenFaultSt.Val
            READ_ChrgIndcr_bRedFaultSt_Val: accessed-variable=ChrgIndcr_bRedFaultSt.Val
            READ_ChrgIndcr_rIndcr{1..3}_Val: accessed-variable=ChrgIndcr_rIndcr{1..3}.Val
            READ_ChrgPlgPosn_st_Val: accessed-variable=ChrgPlgPosn_st.Val
            READ_ChrgPlgPosn_stRaw_Val: accessed-variable=ChrgPlgPosn_stRaw.Val
            READ_ChrgPlgPosn_stRaw2_Val: accessed-variable=ChrgPlgPosn_stRaw2.Val
            READ_ComRx_u8UMM_UsageModeSt_Val: accessed-variable=ComRx_u8UMM_UsageModeSt.Val
            READ_DcChrgrIntkT_flgSRCMaxErr_Val: accessed-variable=DcChrgrIntkT_flgSRCMaxErr.Val
            READ_DcChrgrIntkT_flgSRCMinErr_Val: accessed-variable=DcChrgrIntkT_flgSRCMinErr.Val
            READ_DcChrgrIntkT_t_Val: accessed-variable=DcChrgrIntkT_t.Val
            READ_DcChrgrIntkT2_flgSRCMaxErr_Val: accessed-variable=DcChrgrIntkT2_flgSRCMaxErr.Val
            READ_DcChrgrIntkT2_flgSRCMinErr_Val: accessed-variable=DcChrgrIntkT2_flgSRCMinErr.Val
            READ_DcChrgrIntkT2_t_Val: accessed-variable=DcChrgrIntkT2_t.Val
            READ_DcChrgrPileU1_flgSRCMaxErr_Val: accessed-variable=DcChrgrPileU1_flgSRCMaxErr.Val
            READ_DcChrgrPileU1_flgSRCMinErr_Val: accessed-variable=DcChrgrPileU1_flgSRCMinErr.Val
            READ_DcChrgrPileU1_uRaw_Val: accessed-variable=DcChrgrPileU1_uRaw.Val
            READ_DcChrgrPileU2_flgSRCMaxErr_Val: accessed-variable=DcChrgrPileU2_flgSRCMaxErr.Val
            READ_DcChrgrPileU2_flgSRCMinErr_Val: accessed-variable=DcChrgrPileU2_flgSRCMinErr.Val
            READ_DcChrgrPileU2_uRaw_Val: accessed-variable=DcChrgrPileU2_uRaw.Val
            READ_DcChrgrPileU3_flgSRCMaxErr_Val: accessed-variable=DcChrgrPileU3_flgSRCMaxErr.Val
            READ_DcChrgrPileU3_flgSRCMinErr_Val: accessed-variable=DcChrgrPileU3_flgSRCMinErr.Val
            READ_DcChrgrPileU3_uRaw_Val: accessed-variable=DcChrgrPileU3_uRaw.Val
            READ_IntlckChrgPlg_rActr_Val: accessed-variable=IntlckChrgPlg_rActr.Val
        data-write-access:
          39 x access:
            WRITE_ComTx_bACChgL1TempVoltOvr_Val: accessed-variable=ComTx_bACChgL1TempVoltOvr.Val
            WRITE_ComTx_bACChgL1TempVoltUnd_Val: accessed-variable=ComTx_bACChgL1TempVoltUnd.Val
            WRITE_ComTx_bACChgNTempVoltOvr_Val: accessed-variable=ComTx_bACChgNTempVoltOvr.Val
            WRITE_ComTx_bACChgNTempVoltUnd_Val: accessed-variable=ComTx_bACChgNTempVoltUnd.Val
            WRITE_ComTx_bACEleclocksSt1_Val: accessed-variable=ComTx_bACEleclocksSt1.Val
            WRITE_ComTx_bACEleclocksSt2_Val: accessed-variable=ComTx_bACEleclocksSt2.Val
            WRITE_ComTx_bDCChgDC1TempVoltOvr_Val: accessed-variable=ComTx_bDCChgDC1TempVoltOvr.Val
            WRITE_ComTx_bDCChgDC1TempVoltUnd_Val: accessed-variable=ComTx_bDCChgDC1TempVoltUnd.Val
            WRITE_ComTx_bDCChgDC2TempVoltOvr_Val: accessed-variable=ComTx_bDCChgDC2TempVoltOvr.Val
            WRITE_ComTx_bDCChgDC2TempVoltUnd_Val: accessed-variable=ComTx_bDCChgDC2TempVoltUnd.Val
            WRITE_ComTx_bDCchgpileA1voltVD_Val: accessed-variable=ComTx_bDCchgpileA1voltVD.Val
            WRITE_ComTx_bDCchgpileCC1voltVD_Val: accessed-variable=ComTx_bDCchgpileCC1voltVD.Val
            WRITE_ComTx_bDCchgpileCC2voltVD_Val: accessed-variable=ComTx_bDCchgpileCC2voltVD.Val
            WRITE_ComTx_bEL_BlueChargeLightFaultSt_Val: accessed-variable=ComTx_bEL_BlueChargeLightFaultSt.Val
            WRITE_ComTx_bEL_GreenChargeLightFaultSt_Val: accessed-variable=ComTx_bEL_GreenChargeLightFaultSt.Val
            WRITE_ComTx_bEL_RedChargeLightFaultSt_Val: accessed-variable=ComTx_bEL_RedChargeLightFaultSt.Val
            WRITE_ComTx_u16ACChgL1Temp_Val: accessed-variable=ComTx_u16ACChgL1Temp.Val
            WRITE_ComTx_u16ACChgNTemp_Val: accessed-variable=ComTx_u16ACChgNTemp.Val
            WRITE_ComTx_u16DCChgDC1Temp_Val: accessed-variable=ComTx_u16DCChgDC1Temp.Val
            WRITE_ComTx_u16DCChgDC2emp_Val: accessed-variable=ComTx_u16DCChgDC2emp.Val
            WRITE_ComTx_u16DCChgDC2Temp_Val: accessed-variable=ComTx_u16DCChgDC2Temp.Val
            WRITE_ComTx_u16DCchgpileA1volt_Val: accessed-variable=ComTx_u16DCchgpileA1volt.Val
            WRITE_ComTx_u8ACChgL1TempVD_Val: accessed-variable=ComTx_u8ACChgL1TempVD.Val
            WRITE_ComTx_u8ACChgNTempVD_Val: accessed-variable=ComTx_u8ACChgNTempVD.Val
            WRITE_ComTx_u8ACEleclocksSt_Val: accessed-variable=ComTx_u8ACEleclocksSt.Val
            WRITE_ComTx_u8DCChgDC1TempVD_Val: accessed-variable=ComTx_u8DCChgDC1TempVD.Val
            WRITE_ComTx_u8DCChgDC2TempVD_Val: accessed-variable=ComTx_u8DCChgDC2TempVD.Val
            WRITE_ComTx_u8DCchgpileCC1volt_Val: accessed-variable=ComTx_u8DCchgpileCC1volt.Val
            WRITE_ComTx_u8DCchgpileCC2volt_Val: accessed-variable=ComTx_u8DCchgpileCC2volt.Val
            WRITE_ComTx_u8EL_IndChargeLightSt_Val: accessed-variable=ComTx_u8EL_IndChargeLightSt.Val
            WRITE_ComTx_u8Elecunlockdrvst_Val: accessed-variable=ComTx_u8Elecunlockdrvst.Val
            WRITE_ComTx_u8ElecunlockM1diagnosisoupt_Val: accessed-variable=ComTx_u8ElecunlockM1diagnosisoupt.Val
            WRITE_ComTx_u8ElecunlockM1diagnosisoupt1_Val: accessed-variable=ComTx_u8ElecunlockM1diagnosisoupt1.Val
            WRITE_ComTx_u8ElecunlockM1diagnosisoupt2_Val: accessed-variable=ComTx_u8ElecunlockM1diagnosisoupt2.Val
            WRITE_ComTx_u8ElecunlockM2diagnosisoupt_Val: accessed-variable=ComTx_u8ElecunlockM2diagnosisoupt.Val
            WRITE_ComTx_u8ElecunlockM2diagnosisoupt1_Val: accessed-variable=ComTx_u8ElecunlockM2diagnosisoupt1.Val
            WRITE_ComTx_u8ElecunlockM2diagnosisoupt2_Val: accessed-variable=ComTx_u8ElecunlockM2diagnosisoupt2.Val
            WRITE_ComTx_u8ElecunlockProSt_Val: accessed-variable=ComTx_u8ElecunlockProSt.Val
            WRITE_VehCoorn_stPwrMod_Val: accessed-variable=VehCoorn_stPwrMod.Val
        42 x sync call, all with timeout=1E-06:
          SC_DTC_AcChrgrIntkT2SRCMax_GetEventFailed: operation=DTC_AcChrgrIntkT2SRCMax.GetEventFailed
          SC_DTC_AcChrgrIntkT2SRCMax_GetEventTested: operation=DTC_AcChrgrIntkT2SRCMax.GetEventTested
          SC_DTC_AcChrgrIntkT2SRCMin_GetEventFailed: operation=DTC_AcChrgrIntkT2SRCMin.GetEventFailed
          SC_DTC_AcChrgrIntkT2SRCMin_GetEventTested: operation=DTC_AcChrgrIntkT2SRCMin.GetEventTested
          SC_DTC_AcChrgrIntkTSRCMax_GetEventFailed: operation=DTC_AcChrgrIntkTSRCMax.GetEventFailed
          SC_DTC_AcChrgrIntkTSRCMax_GetEventTested: operation=DTC_AcChrgrIntkTSRCMax.GetEventTested
          SC_DTC_AcChrgrIntkTSRCMin_GetEventFailed: operation=DTC_AcChrgrIntkTSRCMin.GetEventFailed
          SC_DTC_AcChrgrIntkTSRCMin_GetEventTested: operation=DTC_AcChrgrIntkTSRCMin.GetEventTested
          SC_DTC_ChgrPlugLockSnsrErr_GetEventFailed: operation=DTC_ChgrPlugLockSnsrErr.GetEventFailed
          SC_DTC_ChgrPlugLockSnsrErr_GetEventTested: operation=DTC_ChgrPlugLockSnsrErr.GetEventTested
          SC_DTC_DcChrgrIntkT2SRCMax_GetEventFailed: operation=DTC_DcChrgrIntkT2SRCMax.GetEventFailed
          SC_DTC_DcChrgrIntkT2SRCMax_GetEventTested: operation=DTC_DcChrgrIntkT2SRCMax.GetEventTested
          SC_DTC_DcChrgrIntkT2SRCMin_GetEventFailed: operation=DTC_DcChrgrIntkT2SRCMin.GetEventFailed
          SC_DTC_DcChrgrIntkT2SRCMin_GetEventTested: operation=DTC_DcChrgrIntkT2SRCMin.GetEventTested
          SC_DTC_DcChrgrIntkTSRCMax_GetEventFailed: operation=DTC_DcChrgrIntkTSRCMax.GetEventFailed
          SC_DTC_DcChrgrIntkTSRCMax_GetEventTested: operation=DTC_DcChrgrIntkTSRCMax.GetEventTested
          SC_DTC_DcChrgrIntkTSRCMin_GetEventFailed: operation=DTC_DcChrgrIntkTSRCMin.GetEventFailed
          SC_DTC_DcChrgrIntkTSRCMin_GetEventTested: operation=DTC_DcChrgrIntkTSRCMin.GetEventTested
          SC_DTC_DcChrgrPileU1SRCMax_GetEventFailed: operation=DTC_DcChrgrPileU1SRCMax.GetEventFailed
          SC_DTC_DcChrgrPileU1SRCMax_GetEventTested: operation=DTC_DcChrgrPileU1SRCMax.GetEventTested
          SC_DTC_DcChrgrPileU1SRCMin_GetEventFailed: operation=DTC_DcChrgrPileU1SRCMin.GetEventFailed
          SC_DTC_DcChrgrPileU1SRCMin_GetEventTested: operation=DTC_DcChrgrPileU1SRCMin.GetEventTested
          SC_DTC_DcChrgrPileU2SRCMax_GetEventFailed: operation=DTC_DcChrgrPileU2SRCMax.GetEventFailed
          SC_DTC_DcChrgrPileU2SRCMax_GetEventTested: operation=DTC_DcChrgrPileU2SRCMax.GetEventTested
          SC_DTC_DcChrgrPileU2SRCMin_GetEventFailed: operation=DTC_DcChrgrPileU2SRCMin.GetEventFailed
          SC_DTC_DcChrgrPileU2SRCMin_GetEventTested: operation=DTC_DcChrgrPileU2SRCMin.GetEventTested
          SC_DTC_DcChrgrPileU3SRCMax_GetEventFailed: operation=DTC_DcChrgrPileU3SRCMax.GetEventFailed
          SC_DTC_DcChrgrPileU3SRCMax_GetEventTested: operation=DTC_DcChrgrPileU3SRCMax.GetEventTested
          SC_DTC_DcChrgrPileU3SRCMin_GetEventFailed: operation=DTC_DcChrgrPileU3SRCMin.GetEventFailed
          SC_DTC_DcChrgrPileU3SRCMin_GetEventTested: operation=DTC_DcChrgrPileU3SRCMin.GetEventTested
          SC_DTC_IntlckChrgPlgHBrgOL1_GetEventFailed: operation=DTC_IntlckChrgPlgHBrgOL1.GetEventFailed
          SC_DTC_IntlckChrgPlgHBrgOL1_GetEventTested: operation=DTC_IntlckChrgPlgHBrgOL1.GetEventTested
          SC_DTC_IntlckChrgPlgHBrgOL2_GetEventFailed: operation=DTC_IntlckChrgPlgHBrgOL2.GetEventFailed
          SC_DTC_IntlckChrgPlgHBrgOL2_GetEventTested: operation=DTC_IntlckChrgPlgHBrgOL2.GetEventTested
          SC_DTC_IntlckChrgPlgHBrgSCB1_GetEventFailed: operation=DTC_IntlckChrgPlgHBrgSCB1.GetEventFailed
          SC_DTC_IntlckChrgPlgHBrgSCB1_GetEventTested: operation=DTC_IntlckChrgPlgHBrgSCB1.GetEventTested
          SC_DTC_IntlckChrgPlgHBrgSCB2_GetEventFailed: operation=DTC_IntlckChrgPlgHBrgSCB2.GetEventFailed
          SC_DTC_IntlckChrgPlgHBrgSCB2_GetEventTested: operation=DTC_IntlckChrgPlgHBrgSCB2.GetEventTested
          SC_DTC_IntlckChrgPlgHBrgSCG1_GetEventFailed: operation=DTC_IntlckChrgPlgHBrgSCG1.GetEventFailed
          SC_DTC_IntlckChrgPlgHBrgSCG1_GetEventTested: operation=DTC_IntlckChrgPlgHBrgSCG1.GetEventTested
          SC_DTC_IntlckChrgPlgHBrgSCG2_GetEventFailed: operation=DTC_IntlckChrgPlgHBrgSCG2.GetEventFailed
          SC_DTC_IntlckChrgPlgHBrgSCG2_GetEventTested: operation=DTC_IntlckChrgPlgHBrgSCG2.GetEventTested
      runnable ChrgMngt_ComCnvTx_Runnable_Init
  swc implementation ChrgMngt_ComCnvTx_Implementation: behavior=ChrgMngt_ComCnvTx_InternalBehavior
    code-descriptors:
      code Default: artifact-descriptors=autosar-engineering-object={short-label=Default, category=SWSRC}
